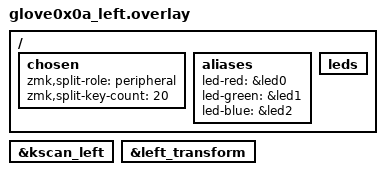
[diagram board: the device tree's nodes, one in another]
#include "glove0x0a_left.dtsi"

// 左手用
&kscan_left {
    status = "okay";
};

&left_transform {
    status = "okay";
};

 / {
    chosen {
        zmk,split-role = "peripheral";
        zmk,split-key-count = <20>;
    };

    aliases {
        led-red = &led0;
        led-green = &led1;
        led-blue = &led2;
    };

    leds {
        status = "okay";
    };
};
